# STM32N655 register map
File version: 1.0
CPU: CM55 r0p1, little endian, no MPU, FPU, vendor SysTick, 8 interrupt priority bits
Registers are 32-bit, read-write, reset 0x0 unless marked. A register's access mark holds for its fields unless they carry their own. Offsets are from the block's base; [hi:lo] are bit positions; {n}, {i} and the like mark numbered series; 'fields as' and 'values as' point back to an identical list.

## RISAF — Resource isolation slave unit for address space protection
Base 0x44026000
Same registers: RISAF_S 0x54026000
0x00 RISAF_CR — RISAF configuration register
  [0] GLOCK — global lock
    0=RISAF registers are writable; 1=All writes to RISAF registers are ignored, except RISAF_IACR, RISAF_REGx_zCFGR, RISAF_REGx_zSTARTR and RISAF_REGx_zENDR (z = A to B)
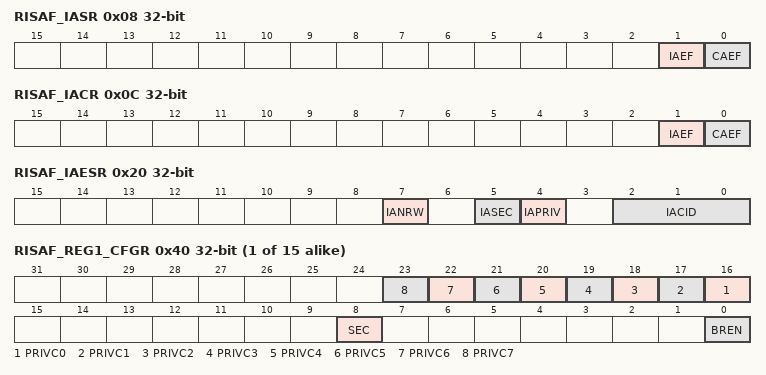
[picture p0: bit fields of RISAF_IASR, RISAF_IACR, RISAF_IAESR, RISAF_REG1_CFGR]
0x08 RISAF_IASR ro — RISAF illegal access status register
  [1] IAEF — illegal access error flag
  [0] CAEF — configuration access error flag
0x0C RISAF_IACR wo — RISAF illegal access clear register
  fields as RISAF_IASR
0x20 RISAF_IAESR ro — RISAF illegal access error status register
  [7] IANRW — illegal access read/write
    0=Illegal access was a data read or an instruction fetch; 1=Illegal access was a data write
  [5] IASEC — illegal access security
    0=Illegal access was non-secure; 1=Illegal access was secure
  [4] IAPRIV — illegal access privileged
    0=Illegal access was unprivileged; 1=Illegal access was privileged
  [2:0] IACID — illegal access compartment ID
0x24 RISAF_IADDR ro — RISAF illegal address register
  [31:0] IADD — illegal address
{0x0+0x40*i} RISAF_REG{i}_CFGR (i=1..15) — RISAF region {i} configuration register
  [n+16] PRIVC{n} (n=0..7) — privileged access for compartment y
    0=Application running in compartment y can access to region x in privileged and unprivileged mode; 1=Application running in compartment y can access to region x in privileged mode only
  [8] SEC — secure region
    0=Only non-secure requests can access region x. SEC value in RISAF_REGx_zCFGR is internally treated as zeroed by RISAF (only non-secure requests to subregions).; 1=Only secure requests can access region x, and optional subregions can be defined as secure or non-secure
  [0] BREN — base region enable
    0=Base region x is disabled. Access control of primary region 0 (secure, privileged) applies to any access between region x start and end addresses. Associated subregions are also disabled.; 1=Base region x is enabled. Access controls defined in region x apply to any access between region x start and end addresses.
{0x4+0x40*i} RISAF_REG{i}_STARTR (i=1..15) — RISAF region {i} start-address register
  [31:0] BADDSTART — Base region address start
{0x8+0x40*i} RISAF_REG{i}_ENDR reset 0xFFF (i=1..15) — RISAF region {i} end-address register
  [31:0] BADDEND — Base region address end
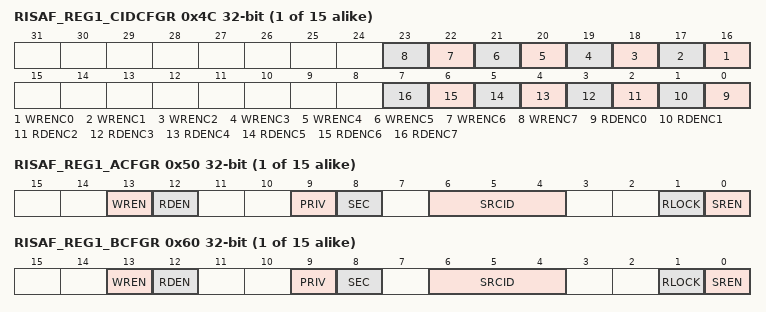
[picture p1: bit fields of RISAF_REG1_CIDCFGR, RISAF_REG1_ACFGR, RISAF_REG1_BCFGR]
{0xC+0x40*i} RISAF_REG{i}_CIDCFGR (i=1..15) — RISAF region {i} CID configuration register
  [n+16] WRENC{n} (n=0..7) — write enable for compartment y
    0=Application running in compartment y cannot write to region x (write ignored); 1=Application running in compartment y can write to region x. Additional control defined by SEC and PRIVCy in RISAF_REGx_CFGR, also apply.
  [n] RDENC{n} (n=0..7) — read enable for compartment y
    0=Application running in compartment y cannot read region x (read as zero); 1=Application running in compartment y can read region x. Additional control defined by SEC and PRIVCy in RISAF_REGx_CFGR, also apply.
{0x10+0x40*i} RISAF_REG{i}_ACFGR (i=1..15) — RISAF region {i} subregion A configuration register
  [13] WREN — write enable
    0=Any writes to subregion z of region x are ignored; 1=Subregion z of region x can be written to
  [12] RDEN — read enable
    0=Any read to subregion z of region x returns zero; 1=Subregion z of region x can be read
  [9] PRIV — privileged subregion
    0=Privileged and unprivileged accesses are granted in subregion z of region x; 1=Only privileged accesses are granted in subregion z of region x
  [8] SEC — secure subregion
    0=Only non-secure requests can access subregion z of region x; 1=Only secure requests can access subregion z of region x
  [6:4] SRCID — subregion CID
  [1] RLOCK — resource lock
    0=RISAF_REGx_zCFGR, RISAF_REGx_zSTARTR and RISAF_REGx_zENDR are writable; 1=Writes to RISAF_REGx_zCFGR, RISAF_REGx_zSTARTR and RISAF_REGx_zENDR are ignored
  [0] SREN — subregion enable
    0=Subregion z is disabled. Access control of base region x applies to any access between this subregion start and end addresses.; 1=Subregion z of region x is enable. Access control defined in subregion z applies to any access between subregion z start and end addresses.
{0x14+0x40*i} RISAF_REG{i}_ASTARTR (i=1..15) — RISAF region {i} subregion A start-address register
  [31:0] SADDSTART — subregion address start
{0x18+0x40*i} RISAF_REG{i}_AENDR reset 0xFFF (i=1..15) — RISAF region {i} subregion A end-address register
  [31:0] SADDEND — subregion address end
{0x1C+0x40*i} RISAF_REG{i}_ANESTR (i=1..15) — RISAF region {i} subregion A nested mode register
  [2] DCEN — delegated configuration enable
    0=RIF configuration for subregion z can be written only by the secure privileged software; 1=RIF configuration for subregion z can be written only
{0x20+0x40*i} RISAF_REG{i}_BCFGR (i=1..15) — RISAF region {i} subregion B configuration register
  fields as RISAF_REG1_ACFGR
{0x24+0x40*i} RISAF_REG{i}_BSTARTR (i=1..15) — RISAF region {i} subregion B start-address register
  [31:0] SADDSTART — subregion address start
{0x28+0x40*i} RISAF_REG{i}_BENDR reset 0xFFF (i=1..15) — RISAF region {i} subregion B end-address register
  [31:0] SADDEND — subregion address end
{0x2C+0x40*i} RISAF_REG{i}_BNESTR (i=1..15) — RISAF region {i} subregion B nested mode register
  fields as RISAF_REG1_ANESTR
